AUTOSAR XML (schema 00051)
package /AUTOSAR/AISpecification/SwComponentTypes_Blueprint/SnsrActrAbstraction
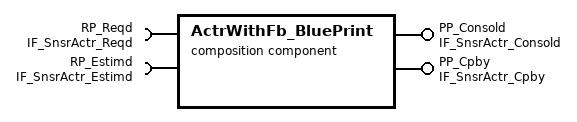
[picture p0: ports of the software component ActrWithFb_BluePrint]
  composition sw component type ActrWithFb_BluePrint
    require port RP_Reqd: required-interface=IF_SnsrActr_Reqd
    provide port PP_Consold: provided-interface=IF_SnsrActr_Consold
    provide port PP_Cpby: provided-interface=IF_SnsrActr_Cpby
    require port RP_Estimd: required-interface=IF_SnsrActr_Estimd
    6 x component:
      CPT_DevCoorrVirt: type=SnsrActr_DevCoorrVirt
      CPT_DevDrvrActr: type=SnsrActr_DevDrvrActr
      CPT_DrvrActrElec: type=SnsrActr_DrvrActrElec
      CPT_DevSnsrVirt: type=SnsrActr_DevSnsrVirt
      CPT_DevDrvrSnsr: type=SnsrActr_DevDrvrSnsr
      CPT_DrvrSnsrElec: type=SnsrActr_DrvrSnsrElec
    delegate CPT_DevCoorrVirt.RP_Reqd <-> outer port ActrWithFb_BluePrint/RP_Reqd
    delegate CPT_DevSnsrVirt.RP_Estimd <-> outer port ActrWithFb_BluePrint/RP_Estimd
    delegate CPT_DevDrvrActr.PP_Cpby <-> outer port ActrWithFb_BluePrint/PP_Cpby
    delegate CPT_DevSnsrVirt.PP_Consold <-> outer port ActrWithFb_BluePrint/PP_Consold
    connect CPT_DevCoorrVirt.PP_Sp -> CPT_DevDrvrActr.RP_Sp
    connect CPT_DevDrvrActr.PP_Outp -> CPT_DrvrActrElec.RP_Outp
    connect CPT_DevSnsrVirt.PP_Consold -> CPT_DevDrvrActr.RP_Consold
    connect CPT_DevDrvrSnsr.PP_Measd -> CPT_DevSnsrVirt.RP_Measd
    connect CPT_DevDrvrSnsr.PP_Raw -> CPT_DevSnsrVirt.RP_Raw
    connect CPT_DrvrSnsrElec.PP_ElecBascFild -> CPT_DevDrvrSnsr.RP_ElecBascFild
    connect CPT_DrvrSnsrElec.PP_ElecRaw -> CPT_DevDrvrSnsr.RP_ElecRaw
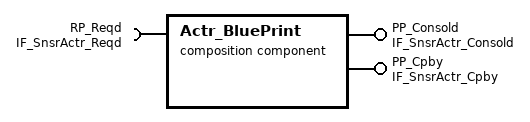
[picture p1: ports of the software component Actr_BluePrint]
  composition sw component type Actr_BluePrint
    require port RP_Reqd: required-interface=IF_SnsrActr_Reqd
    provide port PP_Consold: provided-interface=IF_SnsrActr_Consold
    provide port PP_Cpby: provided-interface=IF_SnsrActr_Cpby
    4 x component:
      CPT_DevCoorrVirt: type=SnsrActr_DevCoorrVirt
      CPT_DevDrvrActr: type=SnsrActr_DevDrvrActr
      CPT_DrvrActrElec: type=SnsrActr_DrvrActrElec
      CPT_DevSnsrVirt: type=SnsrActr_DevSnsrVirt
    delegate CPT_DevCoorrVirt.RP_Reqd <-> outer port Actr_BluePrint/RP_Reqd
    delegate CPT_DevDrvrActr.PP_Cpby <-> outer port Actr_BluePrint/PP_Cpby
    delegate CPT_DevSnsrVirt.PP_Consold <-> outer port Actr_BluePrint/PP_Consold
    connect CPT_DevCoorrVirt.PP_Sp -> CPT_DevDrvrActr.RP_Sp
    connect CPT_DevDrvrActr.PP_Outp -> CPT_DrvrActrElec.RP_Outp
    connect CPT_DevCoorrVirt.PP_Sp -> CPT_DevSnsrVirt.RP_Measd
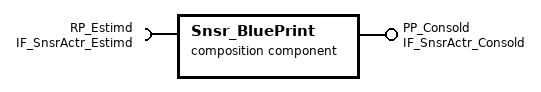
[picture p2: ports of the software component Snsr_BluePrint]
  composition sw component type Snsr_BluePrint
    provide port PP_Consold: provided-interface=IF_SnsrActr_Consold
    require port RP_Estimd: required-interface=IF_SnsrActr_Estimd
    component CPT_DevSnsrVirt: type=SnsrActr_DevSnsrVirt
    component CPT_DevDrvrSnsr: type=SnsrActr_DevDrvrSnsr
    component CPT_DrvrSnsrElec: type=SnsrActr_DrvrSnsrElec
    delegate CPT_DevSnsrVirt.RP_Estimd <-> outer port Snsr_BluePrint/RP_Estimd
    delegate CPT_DevSnsrVirt.PP_Consold <-> outer port Snsr_BluePrint/PP_Consold
    connect CPT_DevDrvrSnsr.PP_Measd -> CPT_DevSnsrVirt.RP_Measd
    connect CPT_DevDrvrSnsr.PP_Raw -> CPT_DevSnsrVirt.RP_Raw
    connect CPT_DrvrSnsrElec.PP_ElecBascFild -> CPT_DevDrvrSnsr.RP_ElecBascFild
    connect CPT_DrvrSnsrElec.PP_ElecRaw -> CPT_DevDrvrSnsr.RP_ElecRaw
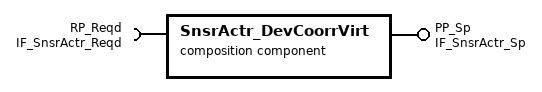
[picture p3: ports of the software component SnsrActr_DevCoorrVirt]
  composition sw component type SnsrActr_DevCoorrVirt
    provide port PP_Sp: provided-interface=IF_SnsrActr_Sp
    require port RP_Reqd: required-interface=IF_SnsrActr_Reqd
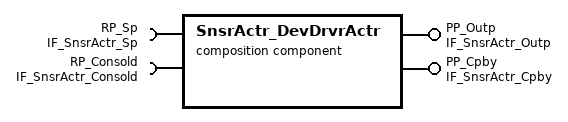
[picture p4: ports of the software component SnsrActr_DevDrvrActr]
  composition sw component type SnsrActr_DevDrvrActr
    provide port PP_Outp: provided-interface=IF_SnsrActr_Outp
    provide port PP_Cpby: provided-interface=IF_SnsrActr_Cpby
    require port RP_Sp: required-interface=IF_SnsrActr_Sp
    require port RP_Consold: required-interface=IF_SnsrActr_Consold
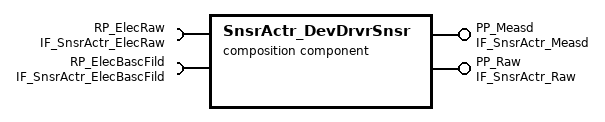
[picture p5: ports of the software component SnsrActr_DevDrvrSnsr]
  composition sw component type SnsrActr_DevDrvrSnsr
    require port RP_ElecRaw: required-interface=IF_SnsrActr_ElecRaw
    require port RP_ElecBascFild: required-interface=IF_SnsrActr_ElecBascFild
    provide port PP_Measd: provided-interface=IF_SnsrActr_Measd
    provide port PP_Raw: provided-interface=IF_SnsrActr_Raw
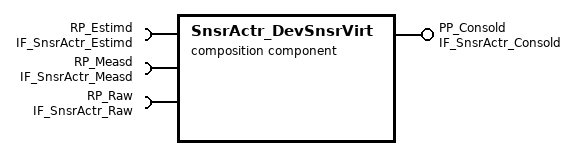
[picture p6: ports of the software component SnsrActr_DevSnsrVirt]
  composition sw component type SnsrActr_DevSnsrVirt
    require port RP_Estimd: required-interface=IF_SnsrActr_Estimd
    require port RP_Measd: required-interface=IF_SnsrActr_Measd
    require port RP_Raw: required-interface=IF_SnsrActr_Raw
    provide port PP_Consold: provided-interface=IF_SnsrActr_Consold
  composition sw component type SnsrActr_DrvrActrElec
    require port RP_Outp: required-interface=IF_SnsrActr_Outp
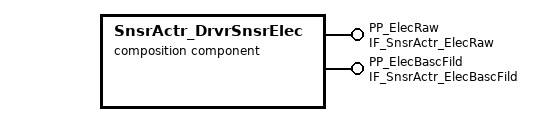
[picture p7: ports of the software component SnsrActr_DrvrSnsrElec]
  composition sw component type SnsrActr_DrvrSnsrElec
    provide port PP_ElecRaw: provided-interface=IF_SnsrActr_ElecRaw
    provide port PP_ElecBascFild: provided-interface=IF_SnsrActr_ElecBascFild
package /AUTOSAR/AISpecification/SwComponentTypes_Blueprint/SnsrActrAbstraction/PortInterfaces
  10 x sender receiver interface:
    IF_SnsrActr_Reqd
    IF_SnsrActr_Consold
    IF_SnsrActr_Cpby
    IF_SnsrActr_Estimd
    IF_SnsrActr_Sp
    IF_SnsrActr_Outp
    IF_SnsrActr_Measd
    IF_SnsrActr_Raw
    IF_SnsrActr_ElecRaw
    IF_SnsrActr_ElecBascFild
